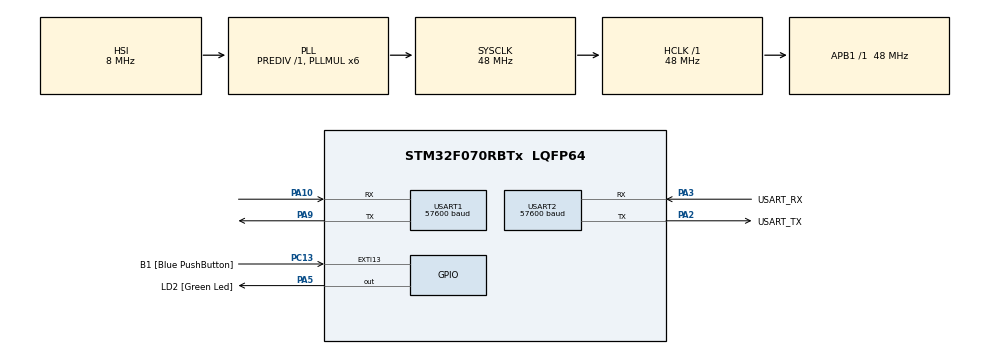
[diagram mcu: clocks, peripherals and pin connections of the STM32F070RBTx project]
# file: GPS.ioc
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FREERTOS.Tasks01=defaultTask,0,128,StartDefaultTask,Default
Mcu.Family=STM32F0
Mcu.Name=STM32F070RBTx
Mcu.Package=LQFP64
NVIC.TIM1_BRK_UP_TRG_COM_IRQn=true\:0\:0\:false
NVIC.TimeBase=TIM1_BRK_UP_TRG_COM_IRQn
NVIC.TimeBaseIP=TIM1
PA10.Mode=Asynchronous
PA10.Signal=USART1_RX
PA13.GPIO_Label=TMS
PA13.Mode=Serial-WireDebug
PA13.Signal=SYS_SWDIO
PA14.Mode=Serial-WireDebug
PA14.Signal=SYS_SWCLK
PA2.GPIO_Label=USART_TX
PA2.Mode=Asynchronous
PA2.Signal=USART2_TX
PA3.GPIO_Label=USART_RX
PA3.Mode=Asynchronous
PA3.Signal=USART2_RX
PA5.GPIO_Label=LD2 [Green Led]
PA5.Signal=GPIO_Output
PA9.Mode=Asynchronous
PA9.Signal=USART1_TX
PC13.GPIO_Label=B1 [Blue PushButton]
PC13.GPIO_ModeDefaultEXTI=GPIO_MODE_EVT_RISING
PC13.Signal=GPXTI13
PC14-OSC32_IN.GPIO_Label=RCC_OSC32_IN
PC14-OSC32_IN.Signal=RCC_OSC32_IN
PC15-OSC32_OUT.GPIO_Label=RCC_OSC32_OUT
PC15-OSC32_OUT.Signal=RCC_OSC32_OUT
PF0-OSC_IN.GPIO_Label=RCC_OSC_IN
PF0-OSC_IN.Signal=RCC_OSC_IN
PF1-OSC_OUT.GPIO_Label=RCC_OSC_OUT
PF1-OSC_OUT.Signal=RCC_OSC_OUT
ProjectManager.HeapSize=0x400
ProjectManager.StackSize=0x200
ProjectManager.TargetToolchain=SW4STM32
RCC.AHBFreq_Value=48000000
RCC.APB1Freq_Value=48000000
RCC.APB1TimFreq_Value=48000000
RCC.HCLKFreq_Value=48000000
RCC.PLLMUL=RCC_PLL_MUL6
RCC.SYSCLKFreq_VALUE=48000000
RCC.SYSCLKSource=RCC_SYSCLKSOURCE_PLLCLK
USART1.BaudRate=57600
USART1.WordLength=UART_WORDLENGTH_8B
USART2.BaudRate=57600
USART2.WordLength=UART_WORDLENGTH_8B
VP_FREERTOS_VS_ENABLE.Mode=Enabled
VP_SYS_VS_tim1.Mode=TIM1
board=NUCLEO-F070RB

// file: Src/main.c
/**
  ******************************************************************************
  * File Name          : main.c
  * Description        : Main program body
  ******************************************************************************
  *
  * COPYRIGHT(c) 2016 STMicroelectronics
  *
  * Redistribution and use in source and binary forms, with or without modification,
  * are permitted provided that the following conditions are met:
  *   1. Redistributions of source code must retain the above copyright notice,
  *      this list of conditions and the following disclaimer.
  *   2. Redistributions in binary form must reproduce the above copyright notice,
  *      this list of conditions and the following disclaimer in the documentation
  *      and/or other materials provided with the distribution.
  *   3. Neither the name of STMicroelectronics nor the names of its contributors
  *      may be used to endorse or promote products derived from this software
  *      without specific prior written permission.
  *
  * THIS SOFTWARE IS PROVIDED BY THE COPYRIGHT HOLDERS AND CONTRIBUTORS "AS IS"
  * AND ANY EXPRESS OR IMPLIED WARRANTIES, INCLUDING, BUT NOT LIMITED TO, THE
  * IMPLIED WARRANTIES OF MERCHANTABILITY AND FITNESS FOR A PARTICULAR PURPOSE ARE
  * DISCLAIMED. IN NO EVENT SHALL THE COPYRIGHT HOLDER OR CONTRIBUTORS BE LIABLE
  * FOR ANY DIRECT, INDIRECT, INCIDENTAL, SPECIAL, EXEMPLARY, OR CONSEQUENTIAL
  * DAMAGES (INCLUDING, BUT NOT LIMITED TO, PROCUREMENT OF SUBSTITUTE GOODS OR
  * SERVICES; LOSS OF USE, DATA, OR PROFITS; OR BUSINESS INTERRUPTION) HOWEVER
  * CAUSED AND ON ANY THEORY OF LIABILITY, WHETHER IN CONTRACT, STRICT LIABILITY,
  * OR TORT (INCLUDING NEGLIGENCE OR OTHERWISE) ARISING IN ANY WAY OUT OF THE USE
  * OF THIS SOFTWARE, EVEN IF ADVISED OF THE POSSIBILITY OF SUCH DAMAGE.
  *
  ******************************************************************************
  */
#include "stm32f0xx_hal.h"
#include "cmsis_os.h"

UART_HandleTypeDef huart1;
UART_HandleTypeDef huart2;

osThreadId defaultTaskHandle;

/* USER CODE BEGIN PV */
/* Private variables ---------------------------------------------------------*/

/* USER CODE END PV */

void SystemClock_Config(void);
static void MX_GPIO_Init(void);
static void MX_USART1_UART_Init(void);
static void MX_USART2_UART_Init(void);
void StartDefaultTask(void const * argument);

/* USER CODE BEGIN PFP */
/* Private function prototypes -----------------------------------------------*/

/* USER CODE END PFP */

int main(void)
{

  /* MCU Configuration----------------------------------------------------------*/

  /* Reset of all peripherals, Initializes the Flash interface and the Systick. */
  HAL_Init();

  /* Configure the system clock */
  SystemClock_Config();

  /* Initialize all configured peripherals */
  MX_GPIO_Init();
  MX_USART1_UART_Init();
  MX_USART2_UART_Init();

  /* Create the thread(s) */
  /* definition and creation of defaultTask */
  osThreadDef(defaultTask, StartDefaultTask, osPriorityNormal, 0, 128);
  defaultTaskHandle = osThreadCreate(osThread(defaultTask), NULL);

  /* Start scheduler */
  osKernelStart();

  /* We should never get here as control is now taken by the scheduler */

  /* Infinite loop */
  while (1)
  {

  }

}

/** System Clock Configuration
*/
void SystemClock_Config(void)
{

  RCC_OscInitTypeDef RCC_OscInitStruct;
  RCC_ClkInitTypeDef RCC_ClkInitStruct;
  RCC_PeriphCLKInitTypeDef PeriphClkInit;

  RCC_OscInitStruct.OscillatorType = RCC_OSCILLATORTYPE_HSI;
  RCC_OscInitStruct.HSIState = RCC_HSI_ON;
  RCC_OscInitStruct.HSICalibrationValue = 16;
  RCC_OscInitStruct.PLL.PLLState = RCC_PLL_ON;
  RCC_OscInitStruct.PLL.PLLSource = RCC_PLLSOURCE_HSI;
  RCC_OscInitStruct.PLL.PLLMUL = RCC_PLL_MUL6;
  RCC_OscInitStruct.PLL.PREDIV = RCC_PREDIV_DIV1;
  HAL_RCC_OscConfig(&RCC_OscInitStruct);

  RCC_ClkInitStruct.ClockType = RCC_CLOCKTYPE_HCLK|RCC_CLOCKTYPE_SYSCLK
                              |RCC_CLOCKTYPE_PCLK1;
  RCC_ClkInitStruct.SYSCLKSource = RCC_SYSCLKSOURCE_PLLCLK;
  RCC_ClkInitStruct.AHBCLKDivider = RCC_SYSCLK_DIV1;
  RCC_ClkInitStruct.APB1CLKDivider = RCC_HCLK_DIV1;
  HAL_RCC_ClockConfig(&RCC_ClkInitStruct, FLASH_LATENCY_1);

  PeriphClkInit.PeriphClockSelection = RCC_PERIPHCLK_USART1;
  PeriphClkInit.Usart1ClockSelection = RCC_USART1CLKSOURCE_PCLK1;
  HAL_RCCEx_PeriphCLKConfig(&PeriphClkInit);

  HAL_SYSTICK_Config(HAL_RCC_GetHCLKFreq()/1000);

  HAL_SYSTICK_CLKSourceConfig(SYSTICK_CLKSOURCE_HCLK);

  /* SysTick_IRQn interrupt configuration */
  HAL_NVIC_SetPriority(SysTick_IRQn, 3, 0);
}

/* USART1 init function */
void MX_USART1_UART_Init(void)
{

  huart1.Instance = USART1;
  huart1.Init.BaudRate = 57600;
  huart1.Init.WordLength = UART_WORDLENGTH_8B;
  huart1.Init.StopBits = UART_STOPBITS_1;
  huart1.Init.Parity = UART_PARITY_NONE;
  huart1.Init.Mode = UART_MODE_TX_RX;
  huart1.Init.HwFlowCtl = UART_HWCONTROL_NONE;
  huart1.Init.OverSampling = UART_OVERSAMPLING_16;
  huart1.Init.OneBitSampling = UART_ONEBIT_SAMPLING_DISABLED ;
  huart1.AdvancedInit.AdvFeatureInit = UART_ADVFEATURE_NO_INIT;
  HAL_UART_Init(&huart1);

}

/* USART2 init function */
void MX_USART2_UART_Init(void)
{

  huart2.Instance = USART2;
  huart2.Init.BaudRate = 57600;
  huart2.Init.WordLength = UART_WORDLENGTH_8B;
  huart2.Init.StopBits = UART_STOPBITS_1;
  huart2.Init.Parity = UART_PARITY_NONE;
  huart2.Init.Mode = UART_MODE_TX_RX;
  huart2.Init.HwFlowCtl = UART_HWCONTROL_NONE;
  huart2.Init.OverSampling = UART_OVERSAMPLING_16;
  huart2.Init.OneBitSampling = UART_ONEBIT_SAMPLING_DISABLED ;
  huart2.AdvancedInit.AdvFeatureInit = UART_ADVFEATURE_NO_INIT;
  HAL_UART_Init(&huart2);

}

/** Configure pins as
        * Analog
        * Input
        * Output
        * EVENT_OUT
        * EXTI
*/
void MX_GPIO_Init(void)
{

  GPIO_InitTypeDef GPIO_InitStruct;

  /* GPIO Ports Clock Enable */
  __GPIOC_CLK_ENABLE();
  __GPIOF_CLK_ENABLE();
  __GPIOA_CLK_ENABLE();

  /*Configure GPIO pin : B1_Pin */
  GPIO_InitStruct.Pin = B1_Pin;
  GPIO_InitStruct.Mode = GPIO_MODE_EVT_RISING;
  GPIO_InitStruct.Pull = GPIO_NOPULL;
  HAL_GPIO_Init(B1_GPIO_Port, &GPIO_InitStruct);

  /*Configure GPIO pin : LD2_Pin */
  GPIO_InitStruct.Pin = LD2_Pin;
  GPIO_InitStruct.Mode = GPIO_MODE_OUTPUT_PP;
  GPIO_InitStruct.Pull = GPIO_NOPULL;
  GPIO_InitStruct.Speed = GPIO_SPEED_LOW;
  HAL_GPIO_Init(LD2_GPIO_Port, &GPIO_InitStruct);

  /*Configure GPIO pin Output Level */
  HAL_GPIO_WritePin(LD2_GPIO_Port, LD2_Pin, GPIO_PIN_RESET);

}

/* StartDefaultTask function */
void StartDefaultTask(void const * argument)
{

  /* USER CODE BEGIN 5 */
	char in[26];
	in[0] = '0';
	uint8_t * nl = "\n\r";
	uint8_t inSize;
	volatile HAL_StatusTypeDef status;

  /* Infinite loop */
	for(;;)
	{
		while(in[0] != '$')
		{
			status = HAL_UART_Receive(&huart1, &in[0], 1, 0x100);
			if(status == HAL_TIMEOUT)	osDelay(150);
		}
		// Receive
		for (inSize = 1; inSize < 25 && status != HAL_TIMEOUT; inSize++)	// max = 25.00\n\r
		{
			status = HAL_UART_Receive(&huart1, &in[inSize], 1, 0x100);
			if(in[inSize] == '\n')	break;
		}
	  	// Send result to PC (opt)
		HAL_UART_Transmit(&huart2, (uint8_t *)in, inSize-1, 0x100);
		in[0] = '0';
		//HAL_UART_Transmit(&huart2, (uint8_t *)nl, 2, 0x100);
		osDelay(150);
	}

  /* USER CODE END 5 */
}

/************************ (C) COPYRIGHT STMicroelectronics *****END OF FILE****/
